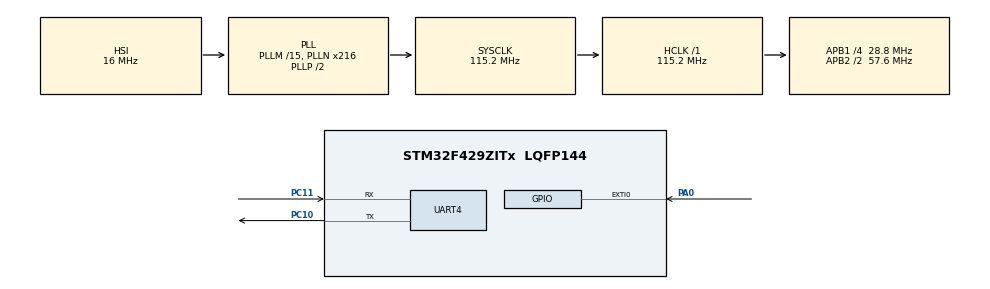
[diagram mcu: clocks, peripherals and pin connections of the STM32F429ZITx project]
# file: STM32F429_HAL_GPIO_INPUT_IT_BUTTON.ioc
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Mcu.Family=STM32F4
RCC.CortexFreq_Value=115200000.00000001
PC11.Signal=UART4_RX
PC10.Signal=UART4_TX
PC10.Mode=Asynchronous
PA0/WKUP.Signal=GPXTI0
RCC.APB1CLKDivider=RCC_HCLK_DIV4
UART4.VirtualMode=Asynchronous
RCC.SYSCLKSource=RCC_SYSCLKSOURCE_PLLCLK
ProjectManager.StackSize=0x400
PA13.Signal=SYS_JTMS-SWDIO
ProjectManager.TargetToolchain=STM32CubeIDE
PH0/OSC_IN.Mode=HSE-External-Clock-Source
RCC.HCLKFreq_Value=115200000.00000001
RCC.APB2TimFreq_Value=115200000.00000001
PH1/OSC_OUT.Signal=RCC_OSC_OUT
RCC.LSE_VALUE=32768
RCC.AHBFreq_Value=115200000.00000001
RCC.HSE_VALUE=25000000
board=custom
RCC.VCOOutputFreq_Value=230400000.00000003
PH0/OSC_IN.Signal=RCC_OSC_IN
RCC.APB2Freq_Value=57600000.00000001
PA14.Mode=Serial_Wire
RCC.INSTRUCTION_CACHE_ENABLE=1
PA0/WKUP.GPIO_ModeDefaultEXTI=GPIO_MODE_IT_RISING_FALLING
PA13.Mode=Serial_Wire
PH1/OSC_OUT.Mode=HSE-External-Clock-Source
Mcu.Name=STM32F429ZITx
RCC.48MHZClocksFreq_Value=57600000.00000001
NVIC.EXTI0_IRQn=true\:0\:0\:false\:false\:true\:true\:true
RCC.SYSCLKFreq_VALUE=115200000.00000001
Mcu.Package=LQFP144
PA14.Signal=SYS_JTCK-SWCLK
ProjectManager.HeapSize=0x200
PC11.Mode=Asynchronous
RCC.HSI_VALUE=16000000
NVIC.PriorityGroup=NVIC_PRIORITYGROUP_4
RCC.APB2CLKDivider=RCC_HCLK_DIV2
RCC.PLLM=15
RCC.PLLN=216
RCC.APB1TimFreq_Value=57600000.00000001
RCC.APB1Freq_Value=28800000.000000004

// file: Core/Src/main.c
/* USER CODE BEGIN Header */
/**
  ******************************************************************************
  * @file           : main.c
  * @brief          : Main program body
  ******************************************************************************
  * @attention
  *
  * <h2><center>&copy; Copyright (c) 2022 STMicroelectronics.
  * All rights reserved.</center></h2>
  *
  * This software component is licensed by ST under BSD 3-Clause license,
  * the "License"; You may not use this file except in compliance with the
  * License. You may obtain a copy of the License at:
  *                        opensource.org/licenses/BSD-3-Clause
  *
  ******************************************************************************
  */
/* USER CODE END Header */
#include "main.h"

/* USER CODE BEGIN PTD */
typedef struct
{
	uint8_t state;
	uint32_t press_time;
	//uint32_t repeat_time;
}s_button;
/* USER CODE END PTD */

/* USER CODE BEGIN PD */
s_button s_button_obj;
/* USER CODE END PD */

/* USER CODE BEGIN PM */
#define CONST_ARRAY(a)     (sizeof(a))/(sizeof(a[0]))
/* USER CODE END PM */

UART_HandleTypeDef huart4;

void SystemClock_Config(void);
static void MX_GPIO_Init(void);
static void MX_UART4_Init(void);
/* USER CODE BEGIN PFP */
void HAL_GPIO_EXTI_Callback(uint16_t GPIO_Pin);
/* USER CODE END PFP */

int main(void)
{

  /* MCU Configuration--------------------------------------------------------*/

  /* Reset of all peripherals, Initializes the Flash interface and the Systick. */
  HAL_Init();

  /* Configure the system clock */
  SystemClock_Config();

  /* Initialize all configured peripherals */
  MX_GPIO_Init();
  MX_UART4_Init();
  /* USER CODE BEGIN 2 */
  s_button_obj.state = 0x0;
  s_button_obj.press_time = HAL_GetTick();
  /* USER CODE END 2 */

  /* Infinite loop */
  while (1)
  {

  }
}

void SystemClock_Config(void)
{
  RCC_OscInitTypeDef RCC_OscInitStruct = {0};
  RCC_ClkInitTypeDef RCC_ClkInitStruct = {0};

  /** Configure the main internal regulator output voltage
  */
  __HAL_RCC_PWR_CLK_ENABLE();
  __HAL_PWR_VOLTAGESCALING_CONFIG(PWR_REGULATOR_VOLTAGE_SCALE3);
  /** Initializes the RCC Oscillators according to the specified parameters
  * in the RCC_OscInitTypeDef structure.
  */
  RCC_OscInitStruct.OscillatorType = RCC_OSCILLATORTYPE_HSI;
  RCC_OscInitStruct.HSIState = RCC_HSI_ON;
  RCC_OscInitStruct.HSICalibrationValue = RCC_HSICALIBRATION_DEFAULT;
  RCC_OscInitStruct.PLL.PLLState = RCC_PLL_ON;
  RCC_OscInitStruct.PLL.PLLSource = RCC_PLLSOURCE_HSI;
  RCC_OscInitStruct.PLL.PLLM = 15;
  RCC_OscInitStruct.PLL.PLLN = 216;
  RCC_OscInitStruct.PLL.PLLP = RCC_PLLP_DIV2;
  RCC_OscInitStruct.PLL.PLLQ = 4;
  if (HAL_RCC_OscConfig(&RCC_OscInitStruct) != HAL_OK)
  {
    Error_Handler();
  }
  /** Initializes the CPU, AHB and APB buses clocks
  */
  RCC_ClkInitStruct.ClockType = RCC_CLOCKTYPE_HCLK|RCC_CLOCKTYPE_SYSCLK
                              |RCC_CLOCKTYPE_PCLK1|RCC_CLOCKTYPE_PCLK2;
  RCC_ClkInitStruct.SYSCLKSource = RCC_SYSCLKSOURCE_PLLCLK;
  RCC_ClkInitStruct.AHBCLKDivider = RCC_SYSCLK_DIV1;
  RCC_ClkInitStruct.APB1CLKDivider = RCC_HCLK_DIV4;
  RCC_ClkInitStruct.APB2CLKDivider = RCC_HCLK_DIV2;

  if (HAL_RCC_ClockConfig(&RCC_ClkInitStruct, FLASH_LATENCY_3) != HAL_OK)
  {
    Error_Handler();
  }
}

static void MX_UART4_Init(void)
{

  huart4.Instance = UART4;
  huart4.Init.BaudRate = 115200;
  huart4.Init.WordLength = UART_WORDLENGTH_8B;
  huart4.Init.StopBits = UART_STOPBITS_1;
  huart4.Init.Parity = UART_PARITY_NONE;
  huart4.Init.Mode = UART_MODE_TX_RX;
  huart4.Init.HwFlowCtl = UART_HWCONTROL_NONE;
  huart4.Init.OverSampling = UART_OVERSAMPLING_16;
  if (HAL_UART_Init(&huart4) != HAL_OK)
  {
    Error_Handler();
  }

}

static void MX_GPIO_Init(void)
{
  GPIO_InitTypeDef GPIO_InitStruct = {0};

  /* GPIO Ports Clock Enable */
  __HAL_RCC_GPIOH_CLK_ENABLE();
  __HAL_RCC_GPIOA_CLK_ENABLE();
  __HAL_RCC_GPIOC_CLK_ENABLE();

  /*Configure GPIO pin : PA0 */
  GPIO_InitStruct.Pin = GPIO_PIN_0;
  GPIO_InitStruct.Mode = GPIO_MODE_IT_RISING_FALLING;
  GPIO_InitStruct.Pull = GPIO_NOPULL;
  HAL_GPIO_Init(GPIOA, &GPIO_InitStruct);

  /* EXTI interrupt init*/
  HAL_NVIC_SetPriority(EXTI0_IRQn, 0, 0);
  HAL_NVIC_EnableIRQ(EXTI0_IRQn);

}

/* USER CODE BEGIN 4 */
void HAL_GPIO_EXTI_Callback(uint16_t GPIO_Pin)
{
	if (GPIO_Pin == GPIO_PIN_0)
	{
       if (HAL_GPIO_ReadPin(GPIOA, GPIO_PIN_0)) //Rising edge
       {
    	   if ( (HAL_GetTick() - s_button_obj.press_time) > 10 ) //10ms
    	   {
    		   s_button_obj.state = 0x01;
    	   }
       }
       else //Falling edge
       {
    	   if (s_button_obj.state == 0x01)
    	   {
              HAL_UART_Transmit(&huart4, (uint8_t *)"Button Release\r\n", sizeof("Button Release\r\n"), 10);
              s_button_obj.state = 0x0;
    	   }
    	   s_button_obj.press_time = HAL_GetTick();
       }
	}
}
/* USER CODE END 4 */

void Error_Handler(void)
{
  __disable_irq();
  while (1)
  {
  }
}

/************************ (C) COPYRIGHT STMicroelectronics *****END OF FILE****/
